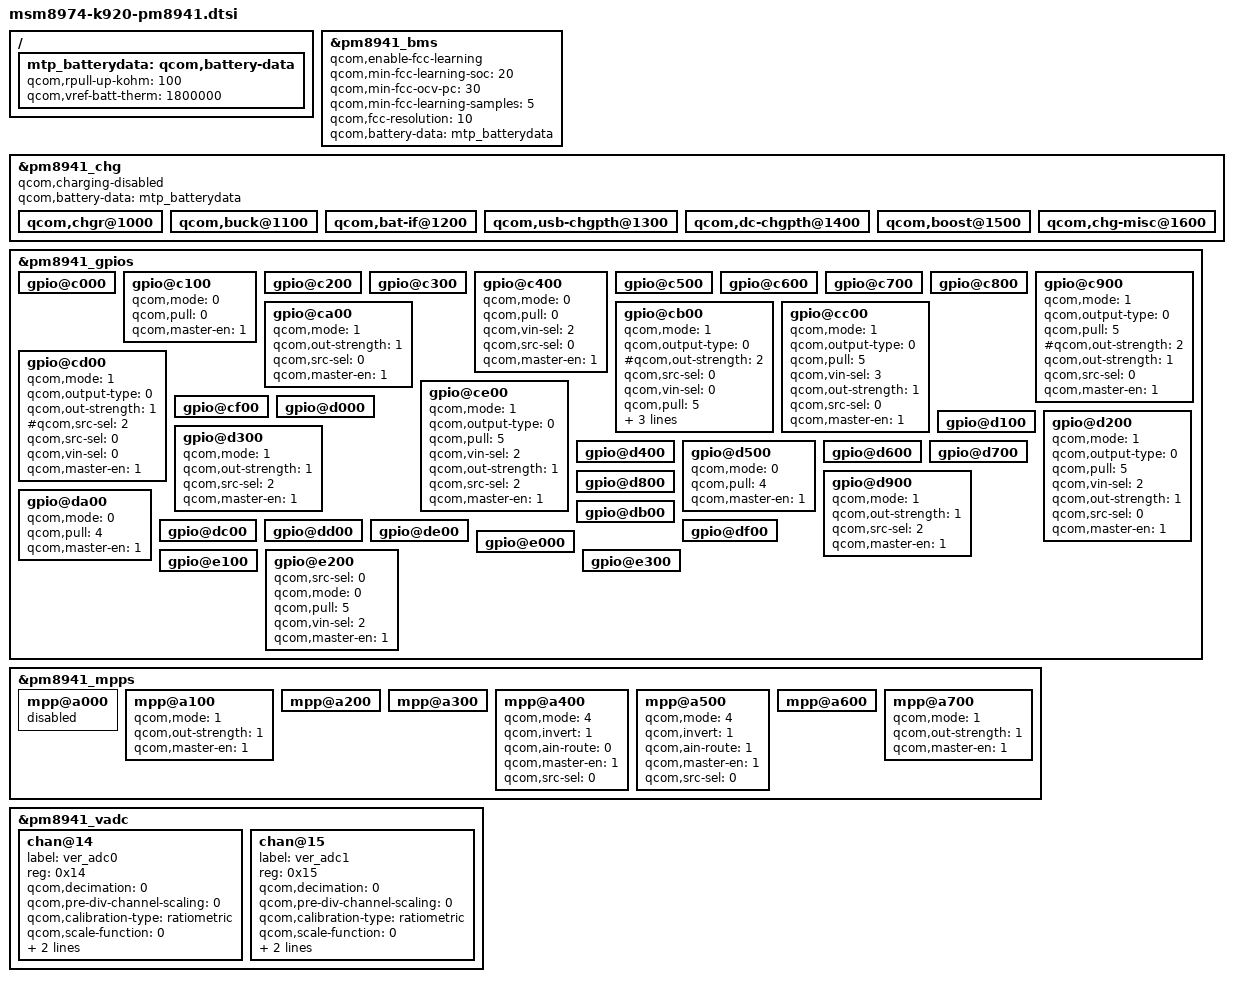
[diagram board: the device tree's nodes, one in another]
/*
 * Copyright (c) 2012-2013, The Linux Foundation. All rights reserved.
 *
 * This program is free software; you can redistribute it and/or modify
 * it under the terms of the GNU General Public License version 2 and
 * only version 2 as published by the Free Software Foundation.
 *
 * This program is distributed in the hope that it will be useful,
 * but WITHOUT ANY WARRANTY; without even the implied warranty of
 * MERCHANTABILITY or FITNESS FOR A PARTICULAR PURPOSE.  See the
 * GNU General Public License for more details.
 */

/ {
	mtp_batterydata: qcom,battery-data {
		qcom,rpull-up-kohm = <100>;
		qcom,vref-batt-therm = <1800000>;

		/include/ "../batterydata-palladium.dtsi"
		/include/ "../batterydata-mtp-3000mah.dtsi"
	};
};

&pm8941_bms {
	qcom,enable-fcc-learning;
	qcom,min-fcc-learning-soc = <20>;
	qcom,min-fcc-ocv-pc = <30>;
	qcom,min-fcc-learning-samples = <5>;
	qcom,fcc-resolution = <10>;
	status = "ok";
	qcom,battery-data = <&mtp_batterydata>;
};

&pm8941_chg {
	status = "ok";
	qcom,charging-disabled;
	qcom,battery-data = <&mtp_batterydata>;

	qcom,chgr@1000 {
		status = "ok";
	};

	qcom,buck@1100 {
		status = "ok";
	};

	qcom,bat-if@1200 {
		status = "ok";
	};

	qcom,usb-chgpth@1300 {
		status = "ok";
	};

	qcom,dc-chgpth@1400 {
		status = "ok";
	};

	qcom,boost@1500 {
		status = "ok";
	};

	qcom,chg-misc@1600 {
		status = "ok";
	};
};


&pm8941_gpios {
	gpio@c000 { /* GPIO 1 */
	};

	gpio@c100 { /* GPIO 2 < VOL_DN_N */
		qcom,mode = <0>;		/* QPNP_PIN_MODE_DIG_IN */
		qcom,pull = <0>;		/* QPNP_PIN_PULL_UP_30 */
		qcom,master-en = <1>;
	};

	gpio@c200 { /* GPIO 3 */
	};

	gpio@c300 { /* GPIO 4 */
	};

	gpio@c400 { /* GPIO 5 < VOL_UP_N */
		qcom,mode = <0>;		/* QPNP_PIN_MODE_DIG_IN */
		qcom,pull = <0>;		/* QPNP_PIN_PULL_UP_30 */
		qcom,vin-sel = <2>;		/* QPNP_PIN_VIN2 */
		qcom,src-sel = <0>;		/* QPNP_PIN_SEL_FUNC_CONSTANT */
		qcom,master-en = <1>;
	};

	gpio@c500 { /* GPIO 6 */
	};

	gpio@c600 { /* GPIO 7 */
	};

	gpio@c700 { /* GPIO 8 */
	};

	gpio@c800 { /* GPIO 9 */
	};

	gpio@c900 { /* GPIO 10 > CHG_EN */
		qcom,mode = <1>;		/* QPNP_PIN_MODE_DIG_OUT */
		qcom,output-type = <0>;		/* CMOS */
		qcom,pull = <5>;		/* PULL_NO */
		#qcom,out-strength = <2>;	/* QPNP_PIN_OUT_STRENGTH_MED */
		qcom,out-strength = <1>;	/* QPNP_PIN_OUT_STRENGTH_LOW */
		qcom,src-sel = <0>;		/* QPNP_PIN_SEL_FUN_CONSTANT */
		qcom,master-en = <1>;
	};

	gpio@ca00 { /* GPIO 11 > CHG_OTG */
		qcom,mode = <1>;		/* QPNP_PIN_MODE_DIG_OUT */
		qcom,out-strength = <1>;	/* QPNP_PIN_OUT_STRENGTH_LOW */
		qcom,src-sel = <0>;		/* QPNP_PIN_SEL_FUNC_ */
		qcom,master-en = <1>;
	};

	gpio@cb00 { /* GPIO 12 > CHG_PSEL */
		qcom,mode = <1>;		/* QPNP_PIN_MODE_DIG_OUT */
		qcom,output-type = <0>;		/* CMOS */
		#qcom,out-strength = <2>;	/* QPNP_PIN_OUT_STRENGTH_MED */
		qcom,src-sel = <0>;		/* QPNP_PIN_SEL_FUN_CONSTANT */
		qcom,vin-sel = <0>;		/* QPNP_PIN_VIN2 */
		qcom,pull = <5>;		/* PULL_NO */
		#qcom,src-sel = <2>;		/* QPNP_PIN_SEL_FUNC_1 */
		qcom,out-strength = <1>;	/* QPNP_PIN_OUT_STRENGTH_LOW */
		qcom,master-en = <1>;
	};

	gpio@cc00 { /* GPIO 13 > LCD_BL_EN */
		qcom,mode = <1>;		/* QPNP_PIN_MODE_DIG_OUT */
		qcom,output-type = <0>;
		qcom,pull = <5>;
		qcom,vin-sel = <3>;
		qcom,out-strength = <1>;	/* QPNP_PIN_OUT_STRENGTH_LOW */
		qcom,src-sel = <0>;		/* function: output 1*/ 
		qcom,master-en = <1>;
	};

	gpio@cd00 { /* GPIO 14 > PMIC_USB_SW_EN */
		qcom,mode = <1>;		/* QPNP_PIN_MODE_DIG_OUT */
		qcom,output-type = <0>;		/* CMOS */
		qcom,out-strength = <1>;	/* QPNP_PIN_OUT_STRENGTH_LOW */
		#qcom,src-sel = <2>;		/* QPNP_PIN_SEL_FUNC_1 */
		qcom,src-sel = <0>;		/* QPNP_PIN_SEL_FUN_CONSTANT */
		qcom,vin-sel = <0>;		/* QPNP_PIN_VIN2 */
		qcom,master-en = <1>;
	};

	gpio@ce00 { /* GPIO 15 > DIVCLK1_CODEC */
		qcom,mode = <1>;
		qcom,output-type = <0>;
		qcom,pull = <5>;
		qcom,vin-sel = <2>;
		qcom,out-strength = <1>;
		qcom,src-sel = <2>;
		qcom,master-en = <1>;
	};

	gpio@cf00 { /* GPIO 16 */
	};

	gpio@d000 { /* GPIO 17 */
	};

	gpio@d100 { /* GPIO 18 */
	};

	gpio@d200 { /* GPIO 19 > DISP_RESET_N */
		qcom,mode = <1>;		/* QPNP_PIN_MODE_DIG_OUT */
		qcom,output-type = <0>;		/* QPNP_PIN_OUT_BUF_CMOS */
		qcom,pull = <5>;		/* QPNP_PIN_PULL_NO */
		qcom,vin-sel = <2>;		/* QPNP_PIN_VIN2 */
		qcom,out-strength = <1>;	/* QPNP_PIN_OUT_STRENGTH_LOW */
		qcom,src-sel = <0>;		/* QPNP_PIN_SEL_FUNC_CONSTANT */
		qcom,master-en = <1>;
	};

	gpio@d300 { /* GPIO 20 > AUDIOJK_SWITCH_EN */
		qcom,mode = <1>;		/* QPNP_PIN_MODE_DIG_OUT */
		qcom,out-strength =<1>;		/* QPNP_PIN_OUT_STRENGTH_LOW */
		qcom,src-sel = <2>;		/* QPNP_PIN_SEL_FUNC_1 */
		qcom,master-en = <1>;
	};

	gpio@d400 { /* GPIO 21 > BOOST_BYP_BYP */
	};

	gpio@d500 { /* GPIO 22 */
		qcom,mode = <0>;		/* QPNP_PIN_MODE_DIG_IN */
		qcom,pull = <4>;		/* QPNP_PIN_PULL_DN */
		qcom,master-en = <1>;
	};

	gpio@d600 { /* GPIO 23 */
	};

	gpio@d700 { /* GPIO 24 */
	};

	gpio@d800 { /* GPIO 25 */
	};

	gpio@d900 { /* GPIO 26 > LCD_BL_PWM */
		qcom,mode = <1>;		/* QPNP_PIN_MODE_DIG_OUT */
		qcom,out-strength = <1>;	/* QPNP_PIN_OUT_STRENGTH_LOW */
		qcom,src-sel = <2>;		/* QPNP_PIN_SEL_FUNC_1 */
		qcom,master-en = <1>;
	};

	gpio@da00 { /* GPIO 27 < FLASH_LED_NOW */
		qcom,mode = <0>;		/* QPNP_PIN_MODE_DIG_IN */
		qcom,pull = <4>;		/* QPNP_PIN_PULL_DN */
		qcom,master-en = <1>;
	};

	gpio@db00 { /* GPIO 28 < TX_GTR_THRES */
	};

	gpio@dc00 { /* GPIO 29 */
	};

	gpio@dd00 { /* GPIO 30 */
	};

	gpio@de00 { /* GPIO 31 > BATT_REM_ALARM */
	};

	gpio@df00 { /* GPIO 32 */
	};

	gpio@e000 { /* GPIO 33 */
	};

	gpio@e100 { /* GPIO 34 */
	};

	gpio@e200 { /* GPIO 35 > XO_OUT_A2_EN */
		//qcom,src-sel = <0>;		/* GPIO */
		qcom,src-sel = <0>;		/* XO_OUT_A2_EN */
		qcom,mode = <0>;		/* QPNP_PIN_MODE_DIG_IN */
		qcom,pull = <5>;		/* QPNP_PIN_PULL_DN --Leon: NP -- */
		qcom,vin-sel = <2>;		/* add pm8941 S3 = 1.8v */
		qcom,master-en = <1>;		/* Enable */
		status = "ok";
	};

	gpio@e300 { /* GPIO 36 */
	};
};

&pm8941_mpps {

	mpp@a000 { /* MPP 1 - SDC_UIM_VBIAS */
		status = "disabled";
	};

	mpp@a100 { /* MPP 2 > CHG_PSEL_MPP02 */
		qcom,mode = <1>;		/* QPNP_PIN_MODE_DIG_OUT */
		qcom,out-strength = <1>;	/* QPNP_PIN_OUT_STRENGTH_LOW */
		qcom,master-en = <1>;
	};

	mpp@a200 { /* MPP 3 < TXDAC0_VREF */
	};

	mpp@a300 { /* MPP 4 */
	};

	mpp@a400 { /* MPP 5 < VER_ADC0 */
		qcom,mode = <4>;		/* AIN input */
		qcom,invert = <1>;		/* Enable MPP */
		qcom,ain-route = <0>;		/* AMUX 5 */
		qcom,master-en = <1>;
		qcom,src-sel = <0>;		/* Function constant */
	};

	mpp@a500 { /* MPP 6 < VER_ADC1 */
		qcom,mode = <4>;		/* AIN input */
		qcom,invert = <1>;		/* Enable MPP */
		qcom,ain-route = <1>;		/* AMUX 6 */
		qcom,master-en = <1>;
		qcom,src-sel = <0>;		/* Function constant */
	};

	mpp@a600 { /* MPP 7 */
	};

	mpp@a700 { /* MPP 8 < USB_CON_THERM */
		qcom,mode = <1>;		/* QPNP_PIN_MODE_DIG_OUT */
		qcom,out-strength = <1>;	/* QPNP_PIN_OUT_STRENGTH_LOW */
		qcom,master-en = <1>;
	};
};

&pm8941_vadc {
	chan@14 {
		label = "ver_adc0";
		reg = <0x14>;
		qcom,decimation = <0>;
		qcom,pre-div-channel-scaling = <0>;
		qcom,calibration-type = "ratiometric";
		qcom,scale-function = <0>;
		qcom,hw-settle-time = <0>;
		qcom,fast-avg-setup = <0>;
	};

	chan@15 {
		label = "ver_adc1";
		reg = <0x15>;
		qcom,decimation = <0>;
		qcom,pre-div-channel-scaling = <0>;
		qcom,calibration-type = "ratiometric";
		qcom,scale-function = <0>;
		qcom,hw-settle-time = <0>;
		qcom,fast-avg-setup = <0>;
	};
};
